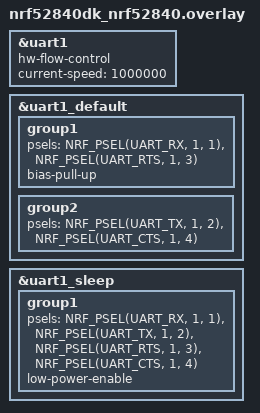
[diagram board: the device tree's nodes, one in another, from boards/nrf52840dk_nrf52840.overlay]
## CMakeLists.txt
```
#
# Copyright (c) 2024 Nordic Semiconductor ASA
#
# SPDX-License-Identifier: LicenseRef-Nordic-5-Clause
#
cmake_minimum_required(VERSION 3.20.0)

find_package(Zephyr REQUIRED HINTS $ENV{ZEPHYR_BASE})

project(nrf_rpc_remote)

# NORDIC SDK APP START
target_sources(app PRIVATE src/main.c)
# NORDIC SDK APP END

# Link OpenThread CLI even though OPENTHREAD_SHELL is not selected
#zephyr_link_libraries(openthread-cli-ftd)
```

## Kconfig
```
#
# Copyright (c) 2024 Nordic Semiconductor ASA
#
# SPDX-License-Identifier: LicenseRef-Nordic-5-Clause
#

menu "Zephyr Kernel"
source "Kconfig.zephyr"
endmenu

module = NRF_RPC_REMOTE
module-str = nrf_rpc_remote
source "${ZEPHYR_BASE}/subsys/logging/Kconfig.template.log_config"
```

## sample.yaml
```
sample:
  name: Protocols serialization server application
  description: Demonstrates serialization of BLE and OpenThread API using nRF RPC
tests:
  applications.protocols_serialization.server.rpc_ble:
    build_only: true
    platform_allow: >
      nrf52840dk/nrf52840
      nrf54l15pdk/nrf54l15/cpuapp
    tags: ci_build
    extra_args: >
      SNIPPET="ble"
    integration_platforms:
      - nrf52840dk/nrf52840
      - nrf54l15pdk/nrf54l15/cpuapp
  applications.protocols_serialization.server.rpc_ot:
    build_only: true
    platform_allow: >
      nrf52840dk/nrf52840
      nrf54l15pdk/nrf54l15/cpuapp
    tags: ci_build
    extra_args: >
      SNIPPET="openthread"
    integration_platforms:
      - nrf52840dk/nrf52840
      - nrf54l15pdk/nrf54l15/cpuapp
  applications.protocols_serialization.server.rpc:
    build_only: true
    platform_allow: >
      nrf52840dk/nrf52840
      nrf54l15pdk/nrf54l15/cpuapp
    tags: ci_build
    extra_args: >
      SNIPPET="ble;openthread"
    integration_platforms:
      - nrf52840dk/nrf52840
      - nrf54l15pdk/nrf54l15/cpuapp
```

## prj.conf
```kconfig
#
# Copyright (c) 2024 Nordic Semiconductor
#
# SPDX-License-Identifier: LicenseRef-Nordic-5-Clause
#
CONFIG_HEAP_MEM_POOL_SIZE=4096

CONFIG_THREAD_CUSTOM_DATA=y

CONFIG_NRF_RPC=y
CONFIG_NRF_RPC_CBOR=y
CONFIG_NRF_RPC_ZCBOR_BACKUPS=1
CONFIG_NRF_RPC_THREAD_STACK_SIZE=4096
CONFIG_NRF_RPC_GROUP_INIT_WAIT_TIME=-1
CONFIG_NRF_RPC_UART_TRANSPORT=y

CONFIG_UART_LINE_CTRL=y
CONFIG_UART_INTERRUPT_DRIVEN=y
```

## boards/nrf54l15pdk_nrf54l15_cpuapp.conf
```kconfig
#
# Copyright (c) 2024 Nordic Semiconductor
#
# SPDX-License-Identifier: LicenseRef-Nordic-5-Clause
#
CONFIG_MAIN_STACK_SIZE=4196
```

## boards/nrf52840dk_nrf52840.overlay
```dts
/* Copyright (c) 2024 Nordic Semiconductor ASA
 *
 * SPDX-License-Identifier: LicenseRef-Nordic-5-Clause
 */

&uart1 {
	status = "okay";
	hw-flow-control;
	current-speed = <1000000>;
};

&uart1_default {
	group1 {
		psels = <NRF_PSEL(UART_RX, 1, 1)>,
			<NRF_PSEL(UART_RTS, 1, 3)>;
		bias-pull-up;
	};
	group2 {
		psels = <NRF_PSEL(UART_TX, 1, 2)>,
			<NRF_PSEL(UART_CTS, 1, 4)>;
	};
};

&uart1_sleep {
	group1 {
		psels = <NRF_PSEL(UART_RX, 1, 1)>,
			<NRF_PSEL(UART_TX, 1, 2)>,
			<NRF_PSEL(UART_RTS, 1, 3)>,
			<NRF_PSEL(UART_CTS, 1, 4)>;
		low-power-enable;
	};
};
```

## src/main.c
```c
/*
 * Copyright (c) 2024 Nordic Semiconductor ASA
 *
 * SPDX-License-Identifier: LicenseRef-Nordic-5-Clause
 */

#include <zephyr/logging/log.h>

#include <nrf_rpc.h>

LOG_MODULE_REGISTER(nrf_rpc_remote, CONFIG_NRF_RPC_REMOTE_LOG_LEVEL);

static void err_handler(const struct nrf_rpc_err_report *report)
{
	LOG_ERR("nRF RPC error %d ocurred. See nRF RPC logs for more details", report->code);
	//k_oops();
}

int main(void)
{
	int ret;

	LOG_INF("Initializing RPC server");

	ret = nrf_rpc_init(err_handler);

	if (ret != 0) {
		LOG_ERR("RPC init failed");
	}

	LOG_INF("RPC server ready");

	return 0;
}
```
